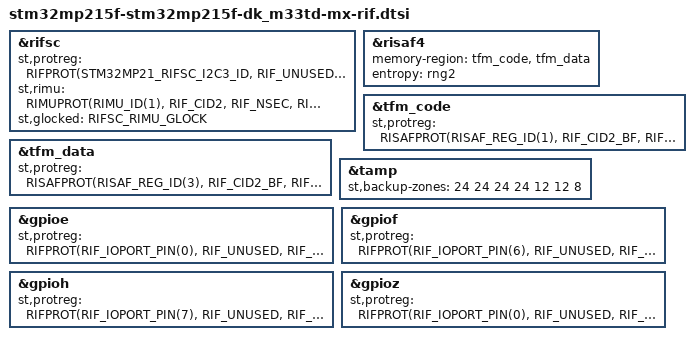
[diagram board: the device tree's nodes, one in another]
// SPDX-License-Identifier: (GPL-2.0-or-later OR BSD-3-Clause)
/*
 * Copyright (C) 2025, STMicroelectronics - All Rights Reserved
 * Author: STM32CubeMX code generation for STMicroelectronics.
 */

/* For more information on Device Tree configuration, please refer to
 * https://wiki.st.com/stm32mpu/wiki/Category:Device_tree_configuration
 */

&rifsc {
	st,protreg = <

		RIFPROT(STM32MP21_RIFSC_I2C3_ID, RIF_UNUSED, RIF_UNLOCK, RIF_SEC, RIF_PRIV, RIF_CID2, RIF_SEM_DIS, RIF_CFEN)
		RIFPROT(STM32MP21_RIFSC_RNG1_ID, RIF_UNUSED, RIF_LOCK, RIF_SEC, RIF_PRIV, RIF_CID2, RIF_SEM_DIS, RIF_CFEN)
		RIFPROT(STM32MP21_RIFSC_RNG2_ID, RIF_UNUSED, RIF_UNLOCK, RIF_SEC, RIF_NPRIV, RIF_CID2, RIF_SEM_DIS, RIF_CFEN)
		RIFPROT(STM32MP21_RIFSC_SDMMC1_ID, RIF_UNUSED, RIF_UNLOCK, RIF_NSEC, RIF_PRIV, RIF_CID2, RIF_SEM_DIS, RIF_CFEN)
		RIFPROT(STM32MP21_RIFSC_UART4_ID, RIF_UNUSED, RIF_UNLOCK, RIF_NSEC, RIF_NPRIV, RIF_CID2, RIF_SEM_DIS, RIF_CFEN)
	>;

	st,rimu = <
		RIMUPROT(RIMU_ID(1), RIF_CID2, RIF_NSEC, RIF_PRIV,RIF_CIDSEL_P) /* RIMU IP = SDMMC1 */
	>;

	st,glocked = <RIFSC_RIMU_GLOCK>;
	status = "okay";

	/* USER CODE BEGIN rifsc */
	/* USER CODE END rifsc */
};

&risaf4 {

	memory-region = <&tfm_code>, <&tfm_data>;
};

&tfm_code {

	st,protreg = <RISAFPROT(RISAF_REG_ID(1), RIF_CID2_BF, RIF_CID2_BF, RIF_UNUSED, RIF_SEC, RIF_ENC_MCE_EN, RIF_BREN_EN)>;
};

&tfm_data {

	st,protreg = <RISAFPROT(RISAF_REG_ID(3), RIF_CID2_BF, RIF_CID2_BF, RIF_UNUSED, RIF_SEC, RIF_ENC_MCE_EN, RIF_BREN_EN)>;
};

&tamp {
	st,backup-zones = <24 24 24 24 12 12 8>;
};

&gpioe {

	st,protreg = <
		RIFPROT(RIF_IOPORT_PIN(0), RIF_UNUSED,  RIF_UNLOCK, RIF_NSEC, RIF_PRIV, RIF_CID1, RIF_SEM_DIS, RIF_CFEN) /* PE0 */
		RIFPROT(RIF_IOPORT_PIN(1), RIF_UNUSED,  RIF_UNLOCK, RIF_NSEC, RIF_PRIV, RIF_CID1, RIF_SEM_DIS, RIF_CFEN) /* PE1 */
		RIFPROT(RIF_IOPORT_PIN(2), RIF_UNUSED,  RIF_UNLOCK, RIF_NSEC, RIF_PRIV, RIF_CID1, RIF_SEM_DIS, RIF_CFEN) /* PE2 */
		RIFPROT(RIF_IOPORT_PIN(3), RIF_UNUSED,  RIF_UNLOCK, RIF_NSEC, RIF_PRIV, RIF_CID1, RIF_SEM_DIS, RIF_CFEN) /* PE3 */
		RIFPROT(RIF_IOPORT_PIN(4), RIF_UNUSED,  RIF_UNLOCK, RIF_NSEC, RIF_PRIV, RIF_CID1, RIF_SEM_DIS, RIF_CFEN) /* PE4 */
		RIFPROT(RIF_IOPORT_PIN(5), RIF_UNUSED,  RIF_UNLOCK, RIF_NSEC, RIF_PRIV, RIF_CID1, RIF_SEM_DIS, RIF_CFEN) /* PE5 */
	>;
};

&gpiof {

	st,protreg = <
		RIFPROT(RIF_IOPORT_PIN(6), RIF_UNUSED,  RIF_UNLOCK, RIF_SEC, RIF_PRIV, RIF_CID2, RIF_SEM_DIS, RIF_CFEN) /* PF6 */
	>;
};

&gpioh {

	st,protreg = <
		RIFPROT(RIF_IOPORT_PIN(7), RIF_UNUSED,  RIF_UNLOCK, RIF_NSEC, RIF_NPRIV, RIF_CID2, RIF_SEM_DIS, RIF_CFEN) /* PH7 */
		RIFPROT(RIF_IOPORT_PIN(8), RIF_UNUSED,  RIF_UNLOCK, RIF_NSEC, RIF_NPRIV, RIF_CID2, RIF_SEM_DIS, RIF_CFEN) /* PH8 */
	>;
};

&gpioz {

	st,protreg = <
		RIFPROT(RIF_IOPORT_PIN(0), RIF_UNUSED,  RIF_UNLOCK, RIF_SEC, RIF_PRIV, RIF_CID2, RIF_SEM_DIS, RIF_CFEN) /* PZ0 */
		RIFPROT(RIF_IOPORT_PIN(1), RIF_UNUSED,  RIF_UNLOCK, RIF_SEC, RIF_PRIV, RIF_CID2, RIF_SEM_DIS, RIF_CFEN) /* PZ1 */
	>;
};

/* USER CODE BEGIN addons */
&risaf4 {
	status = "okay";
	entropy = <&rng2>;
};
/* USER CODE END addons */
